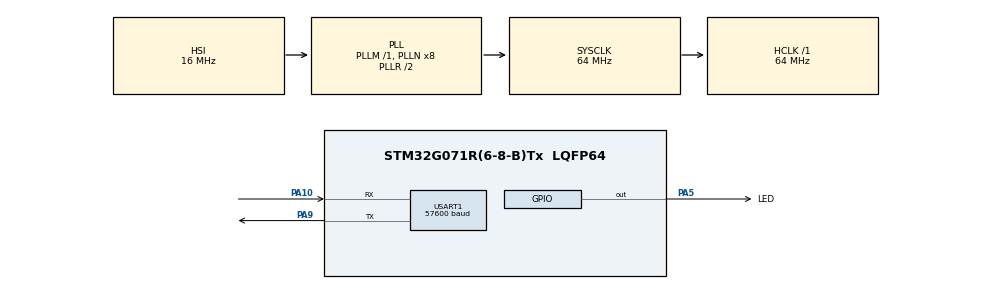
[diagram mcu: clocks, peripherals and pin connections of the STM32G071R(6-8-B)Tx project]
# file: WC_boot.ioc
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CRC.InputDataFormat=CRC_INPUTDATA_FORMAT_WORDS
Mcu.Family=STM32G0
Mcu.Name=STM32G071R(6-8-B)Tx
Mcu.Package=LQFP64
NVIC.USART1_IRQn=true\:0\:0\:false\:false\:true\:true\:true
PA10.Mode=Asynchronous
PA10.Signal=USART1_RX
PA13.Mode=Serial_Wire
PA13.Signal=SYS_SWDIO
PA14-BOOT0.Mode=Serial_Wire
PA14-BOOT0.Signal=SYS_SWCLK
PA5.GPIO_Label=LED
PA5.Signal=GPIO_Output
PA9.Mode=Asynchronous
PA9.Signal=USART1_TX
ProjectManager.HeapSize=0x200
ProjectManager.StackSize=0x400
ProjectManager.TargetToolchain=Makefile
RCC.ADCFreq_Value=64000000
RCC.AHBFreq_Value=64000000
RCC.CortexFreq_Value=64000000
RCC.EXTERNAL_CLOCK_VALUE=48000
RCC.HCLKFreq_Value=64000000
RCC.HSE_VALUE=8000000
RCC.HSI_VALUE=16000000
RCC.LSE_VALUE=32768
RCC.SYSCLKFreq_VALUE=64000000
RCC.SYSCLKSource=RCC_SYSCLKSOURCE_PLLCLK
RCC.VCOOutputFreq_Value=128000000
USART1.BaudRate=57600
USART1.VirtualMode-Asynchronous=VM_ASYNC
VP_CRC_VS_CRC.Mode=CRC_Activate
VP_SYS_VS_DBSignals.Mode=DisableDeadBatterySignals
board=custom

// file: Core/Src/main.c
/* USER CODE BEGIN Header */
/**
  ******************************************************************************
  * @file           : main.c
  * @brief          : Main program body
  ******************************************************************************
  * @attention
  *
  * <h2><center>&copy; Copyright (c) 2022 STMicroelectronics.
  * All rights reserved.</center></h2>
  *
  * This software component is licensed by ST under BSD 3-Clause license,
  * the "License"; You may not use this file except in compliance with the
  * License. You may obtain a copy of the License at:
  *                        opensource.org/licenses/BSD-3-Clause
  *
  ******************************************************************************
  */
/* USER CODE END Header */
#include "main.h"
#include "crc.h"
#include "usart.h"
#include "gpio.h"

/* USER CODE BEGIN Includes */
#include "bootloader.h"
/* USER CODE END Includes */

void SystemClock_Config(void);

int main(void)
{

  /* MCU Configuration--------------------------------------------------------*/

  /* Reset of all peripherals, Initializes the Flash interface and the Systick. */
  HAL_Init();

  /* Configure the system clock */
  SystemClock_Config();

  /* Initialize all configured peripherals */
  MX_GPIO_Init();
  MX_CRC_Init();
  MX_USART1_UART_Init();

  /* Infinite loop */
  /* USER CODE BEGIN WHILE */
  while (1)
  {
    Bootloader_Process();
    /* USER CODE END WHILE */

  }
}

void SystemClock_Config(void)
{
  RCC_OscInitTypeDef RCC_OscInitStruct = {0};
  RCC_ClkInitTypeDef RCC_ClkInitStruct = {0};
  RCC_PeriphCLKInitTypeDef PeriphClkInit = {0};

  /** Configure the main internal regulator output voltage
  */
  HAL_PWREx_ControlVoltageScaling(PWR_REGULATOR_VOLTAGE_SCALE1);
  /** Initializes the RCC Oscillators according to the specified parameters
  * in the RCC_OscInitTypeDef structure.
  */
  RCC_OscInitStruct.OscillatorType = RCC_OSCILLATORTYPE_HSI;
  RCC_OscInitStruct.HSIState = RCC_HSI_ON;
  RCC_OscInitStruct.HSIDiv = RCC_HSI_DIV1;
  RCC_OscInitStruct.HSICalibrationValue = RCC_HSICALIBRATION_DEFAULT;
  RCC_OscInitStruct.PLL.PLLState = RCC_PLL_ON;
  RCC_OscInitStruct.PLL.PLLSource = RCC_PLLSOURCE_HSI;
  RCC_OscInitStruct.PLL.PLLM = RCC_PLLM_DIV1;
  RCC_OscInitStruct.PLL.PLLN = 8;
  RCC_OscInitStruct.PLL.PLLP = RCC_PLLP_DIV2;
  RCC_OscInitStruct.PLL.PLLQ = RCC_PLLQ_DIV2;
  RCC_OscInitStruct.PLL.PLLR = RCC_PLLR_DIV2;
  if (HAL_RCC_OscConfig(&RCC_OscInitStruct) != HAL_OK)
  {
    Error_Handler();
  }
  /** Initializes the CPU, AHB and APB buses clocks
  */
  RCC_ClkInitStruct.ClockType = RCC_CLOCKTYPE_HCLK|RCC_CLOCKTYPE_SYSCLK
                              |RCC_CLOCKTYPE_PCLK1;
  RCC_ClkInitStruct.SYSCLKSource = RCC_SYSCLKSOURCE_PLLCLK;
  RCC_ClkInitStruct.AHBCLKDivider = RCC_SYSCLK_DIV1;
  RCC_ClkInitStruct.APB1CLKDivider = RCC_HCLK_DIV1;

  if (HAL_RCC_ClockConfig(&RCC_ClkInitStruct, FLASH_LATENCY_2) != HAL_OK)
  {
    Error_Handler();
  }
  /** Initializes the peripherals clocks
  */
  PeriphClkInit.PeriphClockSelection = RCC_PERIPHCLK_USART1;
  PeriphClkInit.Usart1ClockSelection = RCC_USART1CLKSOURCE_PCLK1;
  if (HAL_RCCEx_PeriphCLKConfig(&PeriphClkInit) != HAL_OK)
  {
    Error_Handler();
  }
}

void Error_Handler(void)
{
  __disable_irq();
  while (1)
  {
  }
}

/************************ (C) COPYRIGHT STMicroelectronics *****END OF FILE****/
